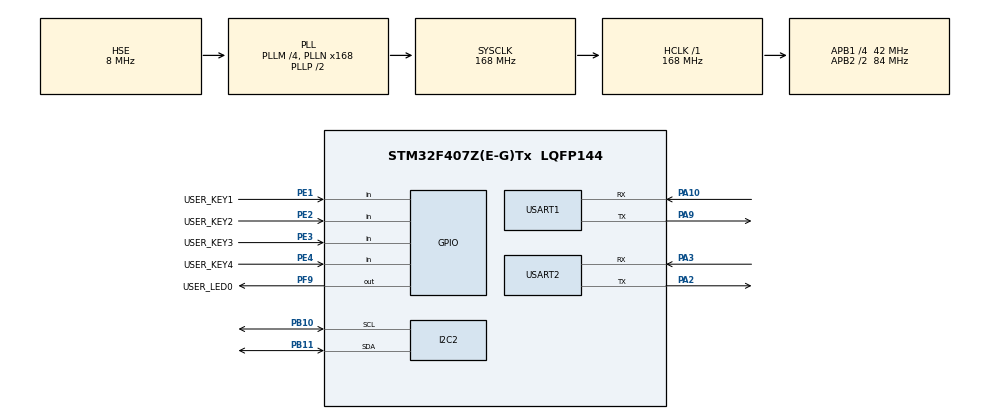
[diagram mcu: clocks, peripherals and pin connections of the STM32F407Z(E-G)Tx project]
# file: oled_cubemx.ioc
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IWDG.Prescaler=IWDG_PRESCALER_256
IWDG.Reload=125
Mcu.Family=STM32F4
Mcu.Name=STM32F407Z(E-G)Tx
Mcu.Package=LQFP144
NVIC.PriorityGroup=NVIC_PRIORITYGROUP_4
NVIC.TIM6_DAC_IRQn=true\:15\:0\:false\:false\:true\:false\:true\:true
NVIC.TimeBase=TIM6_DAC_IRQn
NVIC.TimeBaseIP=TIM6
NVIC.USART1_IRQn=true\:14\:0\:true\:false\:true\:true\:true\:true
NVIC.USART2_IRQn=true\:14\:0\:true\:false\:true\:true\:true\:true
PA10.Mode=Asynchronous
PA10.Signal=USART1_RX
PA13.Mode=Serial_Wire
PA13.Signal=SYS_JTMS-SWDIO
PA14.Mode=Serial_Wire
PA14.Signal=SYS_JTCK-SWCLK
PA2.Mode=Asynchronous
PA2.Signal=USART2_TX
PA3.Mode=Asynchronous
PA3.Signal=USART2_RX
PA9.Mode=Asynchronous
PA9.Signal=USART1_TX
PB10.Mode=I2C
PB10.Signal=I2C2_SCL
PB11.Mode=I2C
PB11.Signal=I2C2_SDA
PC14-OSC32_IN.Mode=LSE-External-Oscillator
PC14-OSC32_IN.Signal=RCC_OSC32_IN
PC15-OSC32_OUT.Mode=LSE-External-Oscillator
PC15-OSC32_OUT.Signal=RCC_OSC32_OUT
PE1.GPIO_Label=USER_KEY1
PE1.Signal=GPIO_Input
PE2.GPIO_Label=USER_KEY2
PE2.Signal=GPIO_Input
PE3.GPIO_Label=USER_KEY3
PE3.Signal=GPIO_Input
PE4.GPIO_Label=USER_KEY4
PE4.Signal=GPIO_Input
PF9.GPIO_Label=USER_LED0
PF9.GPIO_Speed=GPIO_SPEED_FREQ_HIGH
PF9.PinState=GPIO_PIN_SET
PF9.Signal=GPIO_Output
PH0-OSC_IN.Mode=HSE-External-Oscillator
PH0-OSC_IN.Signal=RCC_OSC_IN
PH1-OSC_OUT.Mode=HSE-External-Oscillator
PH1-OSC_OUT.Signal=RCC_OSC_OUT
ProjectManager.HeapSize=0x200
ProjectManager.StackSize=0x1000
ProjectManager.TargetToolchain=MDK-ARM V5.27
RCC.48MHZClocksFreq_Value=84000000
RCC.AHBFreq_Value=168000000
RCC.APB1CLKDivider=RCC_HCLK_DIV4
RCC.APB1Freq_Value=42000000
RCC.APB1TimFreq_Value=84000000
RCC.APB2CLKDivider=RCC_HCLK_DIV2
RCC.APB2Freq_Value=84000000
RCC.APB2TimFreq_Value=168000000
RCC.CortexFreq_Value=168000000
RCC.HCLKFreq_Value=168000000
RCC.HSE_VALUE=8000000
RCC.HSI_VALUE=16000000
RCC.PLLM=4
RCC.PLLN=168
RCC.PLLSourceVirtual=RCC_PLLSOURCE_HSE
RCC.SYSCLKFreq_VALUE=168000000
RCC.SYSCLKSource=RCC_SYSCLKSOURCE_PLLCLK
RCC.VCOOutputFreq_Value=336000000
USART1.VirtualMode=VM_ASYNC
USART2.VirtualMode=VM_ASYNC
VP_IWDG_VS_IWDG.Mode=IWDG_Activate
VP_SYS_VS_tim6.Mode=TIM6
board=custom

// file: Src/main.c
/* USER CODE BEGIN Header */
/**
  ******************************************************************************
  * @file           : main.c
  * @brief          : Main program body
  ******************************************************************************
  * @attention
  *
  * Copyright (c) 2026 STMicroelectronics.
  * All rights reserved.
  *
  * This software is licensed under terms that can be found in the LICENSE file
  * in the root directory of this software component.
  * If no LICENSE file comes with this software, it is provided AS-IS.
  *
  ******************************************************************************
  */
/* USER CODE END Header */
#include "main.h"
#include "i2c.h"
#include "iwdg.h"
#include "usart.h"
#include "gpio.h"

/* USER CODE BEGIN Includes */
#include "user_app.h"
#include "freertos_app.h"
#include "sys_config.h"
/* USER CODE END Includes */

void SystemClock_Config(void);

int main(void)
{

  /* MCU Configuration--------------------------------------------------------*/

  /* Reset of all peripherals, Initializes the Flash interface and the Systick. */
  HAL_Init();

  /* Configure the system clock */
  SystemClock_Config();

  /* USER CODE BEGIN SysInit */

  /* 设置中断向量表偏移 (A/B 槽位，由 APP_SLOT_B 宏控制) */
  sys_config_set_vector_table(APP_VTOR_ADDR);
  /* USER CODE END SysInit */

  /* Initialize all configured peripherals */
  MX_GPIO_Init();
  MX_I2C2_Init();
  MX_USART1_UART_Init();
  MX_USART2_UART_Init();
  MX_IWDG_Init();
  /* USER CODE BEGIN 2 */
  user_app_init();

  freertos_app_init();
  freertos_task_start();
  Error_Handler();
  /* USER CODE END 2 */

  /* Infinite loop */
  while (1)
  {

    /* USER CODE BEGIN 3 */
		//HAL_GPIO_TogglePin(USER_LED0_GPIO_Port, USER_LED0_Pin);
//		user_app_handle();
  }
  /* USER CODE END 3 */
}

void SystemClock_Config(void)
{
  RCC_OscInitTypeDef RCC_OscInitStruct = {0};
  RCC_ClkInitTypeDef RCC_ClkInitStruct = {0};

  /** Configure the main internal regulator output voltage
  */
  __HAL_RCC_PWR_CLK_ENABLE();
  __HAL_PWR_VOLTAGESCALING_CONFIG(PWR_REGULATOR_VOLTAGE_SCALE1);

  /** Initializes the RCC Oscillators according to the specified parameters
  * in the RCC_OscInitTypeDef structure.
  */
  RCC_OscInitStruct.OscillatorType = RCC_OSCILLATORTYPE_LSI|RCC_OSCILLATORTYPE_HSE;
  RCC_OscInitStruct.HSEState = RCC_HSE_ON;
  RCC_OscInitStruct.LSIState = RCC_LSI_ON;
  RCC_OscInitStruct.PLL.PLLState = RCC_PLL_ON;
  RCC_OscInitStruct.PLL.PLLSource = RCC_PLLSOURCE_HSE;
  RCC_OscInitStruct.PLL.PLLM = 4;
  RCC_OscInitStruct.PLL.PLLN = 168;
  RCC_OscInitStruct.PLL.PLLP = RCC_PLLP_DIV2;
  RCC_OscInitStruct.PLL.PLLQ = 4;
  if (HAL_RCC_OscConfig(&RCC_OscInitStruct) != HAL_OK)
  {
    Error_Handler();
  }

  /** Initializes the CPU, AHB and APB buses clocks
  */
  RCC_ClkInitStruct.ClockType = RCC_CLOCKTYPE_HCLK|RCC_CLOCKTYPE_SYSCLK
                              |RCC_CLOCKTYPE_PCLK1|RCC_CLOCKTYPE_PCLK2;
  RCC_ClkInitStruct.SYSCLKSource = RCC_SYSCLKSOURCE_PLLCLK;
  RCC_ClkInitStruct.AHBCLKDivider = RCC_SYSCLK_DIV1;
  RCC_ClkInitStruct.APB1CLKDivider = RCC_HCLK_DIV4;
  RCC_ClkInitStruct.APB2CLKDivider = RCC_HCLK_DIV2;

  if (HAL_RCC_ClockConfig(&RCC_ClkInitStruct, FLASH_LATENCY_5) != HAL_OK)
  {
    Error_Handler();
  }
}

void HAL_TIM_PeriodElapsedCallback(TIM_HandleTypeDef *htim)
{
  if (htim->Instance == TIM6)
  {
    HAL_IncTick();
  }
}

void Error_Handler(void)
{
  __disable_irq();
  while (1)
  {
  }
}
